AUTOSAR XML (schema 00048)
package /SecurityArchitecture/ComponentTypes
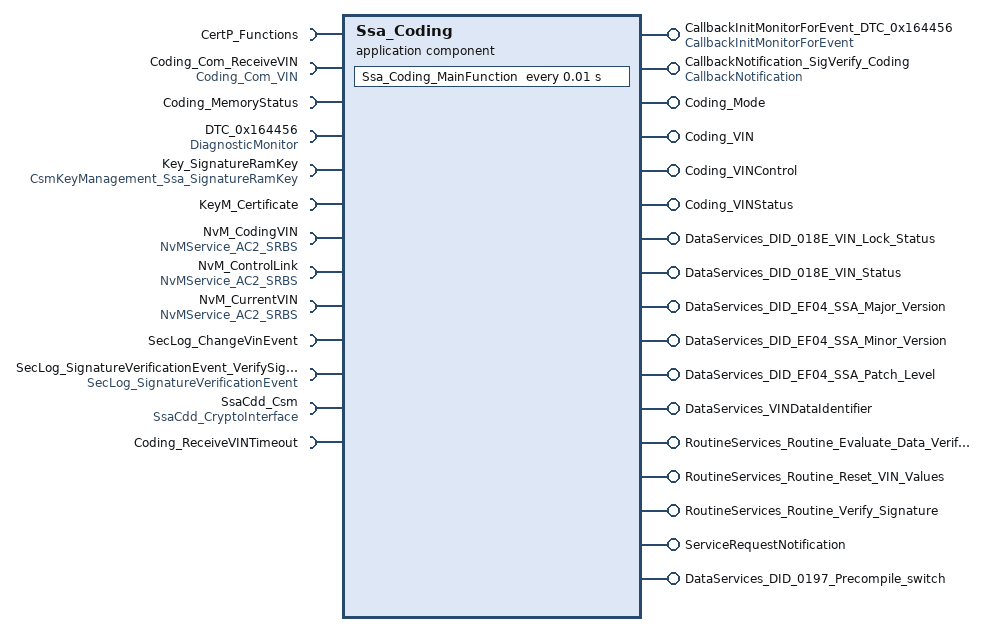
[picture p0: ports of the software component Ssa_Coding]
  application sw component type Ssa_Coding
    16 x provide port:
      CallbackInitMonitorForEvent_DTC_0x164456: server-com-spec{operation=InitMonitorForEvent, queue-length=1}, provided-interface=CallbackInitMonitorForEvent  # Notifies that this event is cleared, or that the operation (monitoring) cycle restarts. Connect to corresponding event of Dem.
      CallbackNotification_SigVerify_Coding: server-com-spec{operation=CallbackNotification, queue-length=1}, provided-interface=CallbackNotification  # Callback notification from the CSM signature verification job used for secure variant coding. Configuration Variant(s): Asynchronous job processing.
      Coding_Mode: mode-switch-sender-com-spec{mode-group=CodingStatus, queue-length=1}, provided-interface=Coding_Mode
      Coding_VIN: server-com-spec{operation=Get, queue-length=1}, provided-interface=Coding_VIN
      Coding_VINControl: provided-interface=Coding_VINControl
        provided-com-specs:
          operation=GetStoreState, queue-length=1
          operation=Lock, queue-length=1
          operation=Set, queue-length=1
      Coding_VINStatus: nonqueued-sender-com-spec{data-element=status, init-value=VIN_STATUS_VIN_CORRECT_RECEIVED}, provided-interface=Coding_VINStatus
      DataServices_DID_018E_VIN_Lock_Status: provided-com-specs=[{operation=ConditionCheckRead, queue-length=1}, {operation=ReadData, queue-length=1}], provided-interface=DataServices_DID_018E_VIN_Lock_Status  # Retrieves the current VIN Lock Status from the ECU. Connect to corresponding Dcm port.
      DataServices_DID_018E_VIN_Status: provided-com-specs=[{operation=ConditionCheckRead, queue-length=1}, {operation=ReadData, queue-length=1}], provided-interface=DataServices_DID_018E_VIN_Status  # Retrieves the current VIN Status from the ECU. Connect to corresponding Dcm port.
      DataServices_DID_EF04_SSA_Major_Version: provided-com-specs=[{operation=ConditionCheckRead, queue-length=1}, {operation=ReadData, queue-length=1}], provided-interface=DataServices_DID_EF04_SSA_Major_Version
      DataServices_DID_EF04_SSA_Minor_Version: provided-com-specs=[{operation=ConditionCheckRead, queue-length=1}, {operation=ReadData, queue-length=1}], provided-interface=DataServices_DID_EF04_SSA_Minor_Version
      DataServices_DID_EF04_SSA_Patch_Level: provided-com-specs=[{operation=ConditionCheckRead, queue-length=1}, {operation=ReadData, queue-length=1}], provided-interface=DataServices_DID_EF04_SSA_Patch_Level
      DataServices_VINDataIdentifier: provided-interface=DataServices_VINDataIdentifier  # Reads and Writes the VIN. Connect to corresponding Dcm port.
        provided-com-specs:
          operation=ConditionCheckRead, queue-length=1
          operation=ReadData, queue-length=1
          operation=WriteData, queue-length=1
      RoutineServices_Routine_Evaluate_Data_Verification_Certificate: server-com-spec{operation=Start, queue-length=1}, provided-interface=RoutineServices_Routine_Evaluate_Data_Verification_Certificate  # Transfer a Signature Verification Key to the ECU, which afterwards will be used for signature verification within software reprogramming or variant coding process. To enable the ECU to validate the Signature Verification Key, the key is transferred within an appropriate certificate.
      RoutineServices_Routine_Reset_VIN_Values: server-com-spec{operation=Start, queue-length=1}, provided-interface=RoutineServices_Routine_Reset_VIN_Values  # Resets the currently stored VINDataIdentifier to its default value.
      RoutineServices_Routine_Verify_Signature: server-com-spec{operation=Start, queue-length=1}, provided-interface=RoutineServices_Routine_Verify_Signature  # Verifies the integrity and authenticity e.g. of variant coding data using a signature verification.
      ServiceRequestNotification: provided-com-specs=[{operation=Confirmation, queue-length=1}, {operation=Indication, queue-length=1}], provided-interface=ServiceRequestNotification  # Indication of a Dcm service request indication which aims for writing of coding relevant data. If request is coding relevant and coding was started, request data is uses as part of signature verification. If request is coding relevant but coding was not started, request is discarded. Connect to corresponding Dcm port.
    12 x require port:
      CertP_Functions: required-interface=CertP_Functions
        required-com-specs:
          AttributeCertificate_Parse
          Certificate_Compare
          Certificate_Parse
          Certificate_Verify
          Certificate_Verify_Extended
          ParseTime
      Coding_Com_ReceiveVIN: nonqueued-receiver-com-spec{data-element=VIN, filter=data-filter-type=ALWAYS, init-value=constant-reference=Ssa_Init_VIN}, required-interface=Coding_Com_VIN  # Configuration Variant(s): Not in VSM.
      Coding_MemoryStatus: mode-switch-receiver-com-spec=MemoryStatus, required-interface=Coding_MemoryStatus
      DTC_0x164456: required-com-specs=[ResetEventDebounceStatus, ResetEventStatus, SetEventStatus], required-interface=DiagnosticMonitor  # Set a Event Status to failed if coding data does not match the current VIN. Connect to corresponding event of Dem.
      Key_SignatureRamKey: required-com-specs=[KeyElementGet, KeyElementSet, KeySetValid], required-interface=CsmKeyManagement_Ssa_SignatureRamKey  # Sets the public key of the coding certificate to verify the signature of the coding data. Connect to a Csm Key which is able to store a public key and is used in the referenced job of the Ssa_Cdd
      KeyM_Certificate: required-interface=KeyM_Certificate
        required-com-specs:
          GetBackendSerialNumber
          GetBackendSubject
          VerifyCertWithBackendCert
          SignData4092ByteWithEcuPrivateKey
          VerifyCertWithBackendCert
          SignData1024ByteWithEcuPrivateKey
          CheckTrustModelChainOfTrust
      NvM_CodingVIN: required-com-specs=[GetErrorStatus, ReadBlock, SetRamBlockStatus, WriteBlock], required-interface=NvMService_AC2_SRBS  # Controlling the NvM block which stores the Coding VIN data. Connect to NvM block storing the Coding VIN.
      NvM_ControlLink: required-com-specs=[GetErrorStatus, ReadBlock, SetRamBlockStatus, WriteBlock], required-interface=NvMService_AC2_SRBS  # Controlling the NvM block which stores coding data. Connect to NvM block storing the coding data. If more than one NvM block is responsible to store coding data use fan-out of Ssa_Cdd instead and configure corresponding NvM block in SSA configuration.
      NvM_CurrentVIN: required-com-specs=[GetErrorStatus, ReadBlock, SetRamBlockStatus, WriteBlock], required-interface=NvMService_AC2_SRBS  # Controlling the NvM block which stores Current VIN data. Connect to NvM block storing the Current VIN.
      SecLog_ChangeVinEvent: client-com-spec=ChangeVin, required-interface=SecLog_ChangeVinEvent
      SecLog_SignatureVerificationEvent_VerifySignatureVariantCoding: client-com-spec=SignatureVerification, required-interface=SecLog_SignatureVerificationEvent
      SsaCdd_Csm: required-com-specs=[CancelJob, SignatureVerify, SignatureGenerate, SignatureVerify, Hash], required-interface=SsaCdd_CryptoInterface
    provide port DataServices_DID_0197_Precompile_switch: provided-com-specs=[{operation=ConditionCheckRead, queue-length=1}, {operation=ReadData, queue-length=1}], provided-interface=DataServices_DID_0197_Precompile_switch  # Retrieves a data field with the status of the precompiled switches from the ECU. Connect to corresponding Dcm port.
    require port Coding_ReceiveVINTimeout: nonqueued-receiver-com-spec{data-element=state, filter=data-filter-type=ALWAYS, init-value=0}, required-interface=Coding_ReceiveVINTimeout  # Configuration Variant(s): Not in VSM.
    behavior Ssa_Coding_InternalBehavior: data-type-mapping=SSATypeMappingSet, included-data-type-set=data-type=Ssa_KeyElementType
      exclusive area Coding_ExclusiveArea_VIN  # This Exclusive area is entered whenever the stored VIN or its attributes are accessed (read or written)
      ar-typed-per-instance-memorys:
        4 x data, all with type=Coding_StorageType:
          CodingVIN
          CodingVINMirror
          CurrentVIN
          CurrentVINMirror
      14 x operation invoked event:
        OIT_Ssa_Coding_CallbackNotification_SigVerify_Coding_CallbackNotification_CallbackNotification_SigVerify_Coding_Callback3DBD4CD5: start-on-event=Ssa_Coding_CsmCallbackNotification_SigVerify_Coding, operation=CallbackNotification_SigVerify_Coding.CallbackNotification
        OIT_DataServices_DID_018E_VIN_Lock_Status_ConditionCheckRead_DataServices_DID_018E_VIN_Lock_Status_ConditionCheckRead: start-on-event=Ssa_Coding_DataServices_DID_018E_VIN_Lock_Status_ConditionCheckRead, operation=DataServices_DID_018E_VIN_Lock_Status.ConditionCheckRead
        OIT_DataServices_DID_018E_VIN_Lock_Status_ReadData_DataServices_DID_018E_VIN_Lock_Status_ReadData: start-on-event=Ssa_Coding_DataServices_DID_018E_VIN_Lock_Status_ReadData, operation=DataServices_DID_018E_VIN_Lock_Status.ReadData
        OIT_DataServices_DID_018E_VIN_Status_ConditionCheckRead_DataServices_DID_018E_VIN_Status_ConditionCheckRead: start-on-event=Ssa_Coding_DataServices_DID_018E_VIN_Status_ConditionCheckRead, operation=DataServices_DID_018E_VIN_Status.ConditionCheckRead
        OIT_DataServices_DID_018E_VIN_Status_ReadData_DataServices_DID_018E_VIN_Status_ReadData: start-on-event=Ssa_Coding_DataServices_DID_018E_VIN_Status_ReadData, operation=DataServices_DID_018E_VIN_Status.ReadData
        OIT_DataServices_DID_EF04_SSA_Major_Version_ConditionCheckRead_DataServices_DID_EF04_SSA_Major_Version_ConditionCheckRead: start-on-event=Ssa_Coding_DataServices_DID_EF04_SSA_Major_Version_ConditionCheckRead, operation=DataServices_DID_EF04_SSA_Major_Version.ConditionCheckRead
        OIT_DataServices_DID_EF04_SSA_Major_Version_ReadData_DataServices_DID_EF04_SSA_Major_Version_ReadData: start-on-event=Ssa_Coding_DataServices_DID_EF04_SSA_Major_Version_ReadData, operation=DataServices_DID_EF04_SSA_Major_Version.ReadData
        OIT_DataServices_DID_EF04_SSA_Minor_Version_ConditionCheckRead_DataServices_DID_EF04_SSA_Minor_Version_ConditionCheckRead: start-on-event=Ssa_Coding_DataServices_DID_EF04_SSA_Minor_Version_ConditionCheckRead, operation=DataServices_DID_EF04_SSA_Minor_Version.ConditionCheckRead
        OIT_DataServices_DID_EF04_SSA_Minor_Version_ReadData_DataServices_DID_EF04_SSA_Minor_Version_ReadData: start-on-event=Ssa_Coding_DataServices_DID_EF04_SSA_Minor_Version_ReadData, operation=DataServices_DID_EF04_SSA_Minor_Version.ReadData
        OIT_DataServices_DID_EF04_SSA_Patch_Level_ConditionCheckRead_DataServices_DID_EF04_SSA_Patch_Level_ConditionCheckRead: start-on-event=Ssa_Coding_DataServices_DID_EF04_SSA_Patch_Level_ConditionCheckRead, operation=DataServices_DID_EF04_SSA_Patch_Level.ConditionCheckRead
        OIT_DataServices_DID_EF04_SSA_Patch_Level_ReadData_DataServices_DID_EF04_SSA_Patch_Level_ReadData: start-on-event=Ssa_Coding_DataServices_DID_EF04_SSA_Patch_Level_ReadData, operation=DataServices_DID_EF04_SSA_Patch_Level.ReadData
        OIT_Ssa_Coding_DataServices_VINDataIdentifier_ConditionCheckRead_DataServices_VINDataIdentifier_ConditionCheckRead: start-on-event=Ssa_Coding_DataServices_VINDataIdentifier_ConditionCheckRead, operation=DataServices_VINDataIdentifier.ConditionCheckRead
        OIT_Ssa_Coding_DataServices_VINDataIdentifier_ReadData_DataServices_VINDataIdentifier_ReadData: start-on-event=Ssa_Coding_DataServices_VINDataIdentifier_ReadData, operation=DataServices_VINDataIdentifier.ReadData
        OIT_Ssa_Coding_DataServices_VINDataIdentifier_WriteData_DataServices_VINDataIdentifier_WriteData: start-on-event=Ssa_Coding_DataServices_VINDataIdentifier_WriteData, operation=DataServices_VINDataIdentifier.WriteData
      init event Coding_InitEvent: start-on-event=Ssa_Coding_Init
      operation invoked event OIT_CallbackInitMonitorForEvent_InitMonitorForEvent_CallbackInitMonitorForEvent_InitMonitorForEvent: start-on-event=Ssa_Coding_InitMonitorForEvent_DTC_0x164456, operation=CallbackInitMonitorForEvent_DTC_0x164456.InitMonitorForEvent
      timing event TMT_Coding_MainFunction: start-on-event=Ssa_Coding_MainFunction, period=0.01
      8 x operation invoked event:
        OIT_Ssa_Coding_RoutineServices_Routine_Evaluate_Data_Verification_Certificate_Start_RoutineServices_Routine_Evaluate_Dat5A8DDCF0: start-on-event=Ssa_Coding_RoutineServices_Routine_Evaluate_Data_Verification_Certificate_Start, operation=RoutineServices_Routine_Evaluate_Data_Verification_Certificate.Start
        OIT_Ssa_Coding_RoutineServices_Routine_Reset_VIN_Values_Start_RoutineServices_Routine_Reset_VIN_Values_Start: start-on-event=Ssa_Coding_RoutineServices_Routine_Reset_VIN_Values_Start, operation=RoutineServices_Routine_Reset_VIN_Values.Start
        OIT_Ssa_Coding_RoutineServices_Routine_Verify_Signature_Start_RoutineServices_Routine_Verify_Signature_Start: start-on-event=Ssa_Coding_RoutineServices_Routine_Verify_Signature_Start, operation=RoutineServices_Routine_Verify_Signature.Start
        OIT_Coding_ServiceRequestNotification_Confirmation_ServiceRequestNotification_Confirmation: start-on-event=Ssa_Coding_ServiceRequestNotification_Confirmation, operation=ServiceRequestNotification.Confirmation
        OIT_Coding_ServiceRequestNotification_Indication_ServiceRequestNotification_Indication: start-on-event=Ssa_Coding_ServiceRequestNotification_Indication, operation=ServiceRequestNotification.Indication
        OIT_Ssa_Coding_VIN_Get_Coding_VIN_Get: start-on-event=Ssa_Coding_VIN_Get, operation=Coding_VIN.Get
        OIT_Ssa_Coding_VIN_GetStoreState_Coding_VINControl_GetStoreState: start-on-event=Ssa_Coding_VIN_GetStoreState, operation=Coding_VINControl.GetStoreState
        OIT_Ssa_Coding_VINControl_Lock_Coding_VINControl_Lock: start-on-event=Ssa_Coding_VIN_Lock, operation=Coding_VINControl.Lock
      data received event DRT_Ssa_Coding_VIN_Receive_Coding_Com_ReceiveVIN_VIN: start-on-event=Ssa_Coding_VIN_Receive, data=Coding_Com_ReceiveVIN.VIN
      operation invoked event OIT_Ssa_Coding_VINControl_Set_Coding_VINControl_Set: start-on-event=Ssa_Coding_VIN_Set, operation=Coding_VINControl.Set
      operation invoked event OIT_DataServices_DID_0197_Precompile_switch_ConditionCheckRead_DataServices_DID_0197_Precompile_switch_ConditionCheckRead: start-on-event=Ssa_Coding_DataServices_DID_0197_Precompile_switch_ConditionCheckRead, operation=DataServices_DID_0197_Precompile_switch.ConditionCheckRead
      operation invoked event OIT_DataServices_DID_0197_Precompile_switch_ReadData_DataServices_DID_0197_Precompile_switch_ReadData: start-on-event=Ssa_Coding_DataServices_DID_0197_Precompile_switch_ReadData, operation=DataServices_DID_0197_Precompile_switch.ReadData
      data received event DRT_Ssa_Coding_VIN_Receive_Timeout_Coding_ReceiveVINTimeout_state: start-on-event=Ssa_Coding_VIN_Receive_Timeout, data=Coding_ReceiveVINTimeout.state
      port-api-options:
        enable-take-address=false, error-handling=NO-TRANSFORMER-ERROR-HANDLING, indirect-api=false, port=CallbackInitMonitorForEvent_DTC_0x164456
        enable-take-address=false, error-handling=NO-TRANSFORMER-ERROR-HANDLING, indirect-api=false, port=CertP_Functions
        enable-take-address=false, error-handling=NO-TRANSFORMER-ERROR-HANDLING, indirect-api=false, port=Coding_Com_ReceiveVIN
        enable-take-address=false, error-handling=NO-TRANSFORMER-ERROR-HANDLING, indirect-api=false, port=Coding_Mode
        enable-take-address=false, error-handling=NO-TRANSFORMER-ERROR-HANDLING, indirect-api=false, port=Coding_VIN
        enable-take-address=false, error-handling=NO-TRANSFORMER-ERROR-HANDLING, indirect-api=false, port=Coding_VINControl
        enable-take-address=false, error-handling=NO-TRANSFORMER-ERROR-HANDLING, indirect-api=false, port=Coding_VINStatus
        enable-take-address=false, error-handling=NO-TRANSFORMER-ERROR-HANDLING, indirect-api=false, port=DataServices_DID_EF04_SSA_Major_Version
        enable-take-address=false, error-handling=NO-TRANSFORMER-ERROR-HANDLING, indirect-api=false, port=DataServices_DID_EF04_SSA_Minor_Version
        enable-take-address=false, error-handling=NO-TRANSFORMER-ERROR-HANDLING, indirect-api=false, port=DataServices_DID_EF04_SSA_Patch_Level
        enable-take-address=false, error-handling=NO-TRANSFORMER-ERROR-HANDLING, indirect-api=false, port=DataServices_VINDataIdentifier
        enable-take-address=false, error-handling=NO-TRANSFORMER-ERROR-HANDLING, indirect-api=false, port=DTC_0x164456
        enable-take-address=false, error-handling=NO-TRANSFORMER-ERROR-HANDLING, indirect-api=false, port=Key_SignatureRamKey
        enable-take-address=false, error-handling=NO-TRANSFORMER-ERROR-HANDLING, indirect-api=false, port=KeyM_Certificate
        enable-take-address=false, error-handling=NO-TRANSFORMER-ERROR-HANDLING, indirect-api=false, port=NvM_ControlLink
        enable-take-address=false, error-handling=NO-TRANSFORMER-ERROR-HANDLING, indirect-api=false, port=NvM_CurrentVIN
        enable-take-address=false, error-handling=NO-TRANSFORMER-ERROR-HANDLING, indirect-api=false, port=SecLog_ChangeVinEvent
        enable-take-address=false, error-handling=NO-TRANSFORMER-ERROR-HANDLING, indirect-api=false, port=SecLog_SignatureVerificationEvent_VerifySignatureVariantCoding
        enable-take-address=false, error-handling=NO-TRANSFORMER-ERROR-HANDLING, indirect-api=false, port=ServiceRequestNotification
        enable-take-address=false, error-handling=NO-TRANSFORMER-ERROR-HANDLING, indirect-api=false, port=SsaCdd_Csm
      30 x runnable:
        Ssa_Coding_CsmCallbackNotification_SigVerify_Coding  # Configuration Variant(s): Asynchronous job processing.
        Ssa_Coding_DataServices_DID_018E_VIN_Lock_Status_ConditionCheckRead
        Ssa_Coding_DataServices_DID_018E_VIN_Lock_Status_ReadData
        Ssa_Coding_DataServices_DID_018E_VIN_Status_ConditionCheckRead
        Ssa_Coding_DataServices_DID_018E_VIN_Status_ReadData
        Ssa_Coding_DataServices_DID_EF04_SSA_Major_Version_ConditionCheckRead
        Ssa_Coding_DataServices_DID_EF04_SSA_Major_Version_ReadData
        Ssa_Coding_DataServices_DID_EF04_SSA_Minor_Version_ConditionCheckRead
        Ssa_Coding_DataServices_DID_EF04_SSA_Minor_Version_ReadData
        Ssa_Coding_DataServices_DID_EF04_SSA_Patch_Level_ConditionCheckRead
        Ssa_Coding_DataServices_DID_EF04_SSA_Patch_Level_ReadData
        Ssa_Coding_DataServices_VINDataIdentifier_ConditionCheckRead
        Ssa_Coding_DataServices_VINDataIdentifier_ReadData: can-enter-exclusive-area=Coding_ExclusiveArea_VIN
        Ssa_Coding_DataServices_VINDataIdentifier_WriteData: can-enter-exclusive-area=Coding_ExclusiveArea_VIN
          data-send-points:
            access SEND_Coding_Flag_status: accessed-variable=Coding_VINStatus.status
          sync call SC_Dem_CodingStatus_SetEventStatus: operation=DTC_0x164456.SetEventStatus
          sync call SC_SecLog_ChangeVinEvent_ChangeVin: operation=SecLog_ChangeVinEvent.ChangeVin
          sync call SC_SsaCdd_Csm_CancelJob: operation=SsaCdd_Csm.CancelJob
        Ssa_Coding_Init
          data-send-points:
            access SEND_Coding_Flag_status: accessed-variable=Coding_VINStatus.status
        Ssa_Coding_InitMonitorForEvent_DTC_0x164456
          sync call SC_DTC_0x164456_SetEventStatus: operation=DTC_0x164456.SetEventStatus
        Ssa_Coding_MainFunction: can-enter-exclusive-area=Coding_ExclusiveArea_VIN
          data-send-points:
            access SEND_Coding_VINStatus_status: accessed-variable=Coding_VINStatus.status
          mode switch point SWITCH_Coding_Mode_CodingStatus: mode-group=Coding_Mode.CodingStatus
          7 x sync call:
            SC_NvM_CodingVIN_GetErrorStatus: operation=NvM_CodingVIN.GetErrorStatus
            SC_NvM_CodingVIN_WriteBlock: operation=NvM_CodingVIN.WriteBlock
            SC_NvM_ControlLink_GetErrorStatus: operation=NvM_ControlLink.GetErrorStatus
            SC_NvM_ControlLink_ReadBlock: operation=NvM_ControlLink.ReadBlock
            SC_NvM_VIN_GetErrorStatus: operation=NvM_CurrentVIN.GetErrorStatus
            SC_NvM_VIN_WriteBlock: operation=NvM_CurrentVIN.WriteBlock
            SC_SsaCdd_Csm_CancelJob: operation=SsaCdd_Csm.CancelJob
        Ssa_Coding_RoutineServices_Routine_Evaluate_Data_Verification_Certificate_Start: can-enter-exclusive-area=Coding_ExclusiveArea_VIN, mode-access-point=Coding_MemoryStatus.MemoryStatus
          data-send-points:
            access SEND_Coding_VINStatus_status: accessed-variable=Coding_VINStatus.status
          mode switch point SWITCH_Coding_Mode_CodingStatus: mode-group=Coding_Mode.CodingStatus
          6 x sync call:
            SC_CertP_Functions_Certificate_Parse: operation=CertP_Functions.Certificate_Parse
            SC_Key_SignatureRamKey_KeyElementSet: operation=Key_SignatureRamKey.KeyElementSet
            SC_Key_SignatureRamKey_KeySetValid: operation=Key_SignatureRamKey.KeySetValid
            SC_KeyM_Certificate_VerifyCertWithBackendCert: operation=KeyM_Certificate.VerifyCertWithBackendCert
            SC_SsaCdd_Csm_CancelJob: operation=SsaCdd_Csm.CancelJob
            SC_SsaCdd_Csm_SignatureVerify: operation=SsaCdd_Csm.SignatureVerify
        Ssa_Coding_RoutineServices_Routine_Reset_VIN_Values_Start: can-enter-exclusive-area=Coding_ExclusiveArea_VIN
          data-send-points:
            access SEND_Coding_VINStatus_status: accessed-variable=Coding_VINStatus.status
          sync call SC_DTC_0x164456_SetEventStatus: operation=DTC_0x164456.SetEventStatus
          sync call SC_SecLog_ChangeVinEvent_ChangeVin: operation=SecLog_ChangeVinEvent.ChangeVin
          sync call SC_SsaCdd_Csm_CancelJob: operation=SsaCdd_Csm.CancelJob
        Ssa_Coding_RoutineServices_Routine_Verify_Signature_Start: can-enter-exclusive-area=Coding_ExclusiveArea_VIN, mode-access-point=Coding_MemoryStatus.MemoryStatus
          data-send-points:
            access SEND_Coding_VINStatus_status: accessed-variable=Coding_VINStatus.status
          mode switch point SWITCH_Coding_Mode_CodingStatus: mode-group=Coding_Mode.CodingStatus
          7 x sync call:
            SC_NvM_ControlLink_GetErrorStatus: operation=NvM_ControlLink.GetErrorStatus
            SC_NvM_ControlLink_ReadBlock: operation=NvM_ControlLink.ReadBlock
            SC_NvM_ControlLink_SetRamBlockStatus: operation=NvM_ControlLink.SetRamBlockStatus
            SC_NvM_ControlLink_WriteBlock: operation=NvM_ControlLink.WriteBlock
            SC_SecLog_SignatureVerificationEvent_VerifySignatureVariantCoding_SignatureVerification: operation=SecLog_SignatureVerificationEvent_VerifySignatureVariantCoding.SignatureVerification
            SC_SsaCdd_Csm_CancelJob: operation=SsaCdd_Csm.CancelJob
            SC_SsaCdd_Csm_SignatureVerify: operation=SsaCdd_Csm.SignatureVerify
        Ssa_Coding_ServiceRequestNotification_Confirmation
        Ssa_Coding_ServiceRequestNotification_Indication
          sync call SC_SsaCdd_Csm_CancelJob: operation=SsaCdd_Csm.CancelJob
          sync call SC_SsaCdd_Csm_SignatureVerify: operation=SsaCdd_Csm.SignatureVerify
        Ssa_Coding_VIN_Get: can-enter-exclusive-area=Coding_ExclusiveArea_VIN, can-be-invoked-concurrently=true
        Ssa_Coding_VIN_GetStoreState
        Ssa_Coding_VIN_Lock: can-enter-exclusive-area=Coding_ExclusiveArea_VIN
        Ssa_Coding_VIN_Receive: can-enter-exclusive-area=Coding_ExclusiveArea_VIN  # Configuration Variant(s): Not in VSM.
          data-receive-point-by-arguments:
            access REC_Coding_Com_ReceiveVIN_VIN: accessed-variable=Coding_Com_ReceiveVIN.VIN
          data-send-points:
            access SEND_Coding_Flag_status: accessed-variable=Coding_VINStatus.status
          sync call SC_Dem_CodingStatus_SetEventStatus: operation=DTC_0x164456.SetEventStatus
          sync call SC_SecLog_ChangeVinEvent_ChangeVin: operation=SecLog_ChangeVinEvent.ChangeVin
          sync call SC_SsaCdd_Csm_CancelJob: operation=SsaCdd_Csm.CancelJob
        Ssa_Coding_VIN_Set: can-enter-exclusive-area=Coding_ExclusiveArea_VIN
          data-send-points:
            access SEND_Coding_Flag_status: accessed-variable=Coding_VINStatus.status
          sync call SC_Dem_CodingStatus_SetEventStatus: operation=DTC_0x164456.SetEventStatus
          sync call SC_SecLog_ChangeVinEvent_ChangeVin: operation=SecLog_ChangeVinEvent.ChangeVin
          sync call SC_SsaCdd_Csm_CancelJob: operation=SsaCdd_Csm.CancelJob
        Ssa_Coding_DataServices_DID_0197_Precompile_switch_ConditionCheckRead: can-be-invoked-concurrently=true
        Ssa_Coding_DataServices_DID_0197_Precompile_switch_ReadData: can-be-invoked-concurrently=true
          sync call SC_KeyM_Certificate_CheckTrustModelChainOfTrust: operation=KeyM_Certificate.CheckTrustModelChainOfTrust
        Ssa_Coding_VIN_Receive_Timeout  # Configuration Variant(s): Not in VSM.
      swc service dependency NvM_Coding_CurrentVIN
        assigned-datas:
          role=ramBlock, used-data-element=CurrentVIN
          role=defaultValue, used-parameter-element=Coding_Storage_DefaultValue
        service-needs:
          nv block needs NvM_Coding_CurrentVIN: ram-block-status-control=API, restore-at-start=true, store-at-shutdown=false
      swc service dependency NvM_Coding_CodingVIN
        assigned-datas:
          role=ramBlock, used-data-element=CodingVIN
          role=defaultValue, used-parameter-element=Coding_Storage_DefaultValue
        service-needs:
          nv block needs NvM_Coding_CodingVIN: ram-block-status-control=API, restore-at-start=true, store-at-shutdown=false
      shared-parameters:
        parameter data prototype Coding_Storage_DefaultValue: type=Coding_StorageType, init-value=constant-reference=Ssa_Coding_Init_VINStorage
  swc implementation Ssa_Coding_Implementation: behavior=Ssa_Coding_InternalBehavior
    code-descriptors:
      code Default: artifact-descriptors=autosar-engineering-object=category=SWSRC
